# M7 register map
Registers are 32-bit, read-write, reset 0x0 unless marked. A register's access mark holds for its fields unless they carry their own. Offsets are from the block's base; lines under a group give offsets from that group; [hi:lo] are bit positions; {n}, {i} and the like mark numbered series; 'fields as' and 'values as' point back to an identical list; <NAME> marks a mode.

## Memory map
0xE000E010 STK size 0x11 — SysTick timer
0xE000E100 NVIC size 0x3C5 — Nested Vectored Interrupt Controller
0xE000ED00 SCB size 0x41 — System control block
0xE000ED90 MPU size 0x15 — Memory protection unit
0xE000EF34 FPU size 0xD — Floting point unit

## FPU — Floting point unit
Base 0xE000EF34
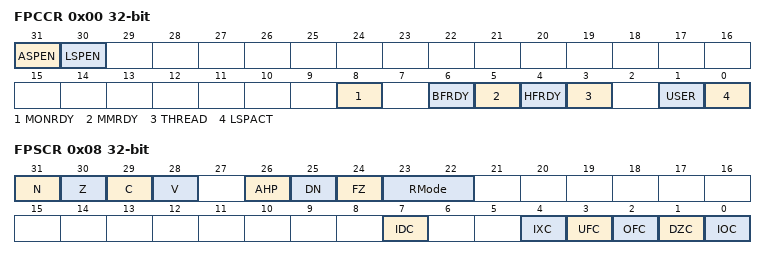
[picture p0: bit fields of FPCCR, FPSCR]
0x00 FPCCR — Floating-point context control register
  [31] ASPEN, [30] LSPEN, [8] MONRDY, [6] BFRDY, [5] MMRDY, [4] HFRDY, [3] THREAD, [1] USER, [0] LSPACT
0x04 FPCAR — Floating-point context address register
  [31:3] ADDRESS — Location of unpopulated floating-point
0x08 FPSCR — Floating-point status control register
  [31] N — Negative condition code flag
  [30] Z — Zero condition code flag
  [29] C — Carry condition code flag
  [28] V — Overflow condition code flag
  [26] AHP — Alternative half-precision control bit
  [25] DN — Default NaN mode control bit
  [24] FZ — Flush-to-zero mode control bit:
  [23:22] RMode — Rounding Mode control field
  [7] IDC — Input denormal cumulative exception bit.
  [4] IXC — Inexact cumulative exception bit
  [3] UFC — Underflow cumulative exception bit
  [2] OFC — Overflow cumulative exception bit
  [1] DZC — Division by zero cumulative exception bit.
  [0] IOC — Invalid operation cumulative exception bit

## MPU — Memory protection unit
Base 0xE000ED90
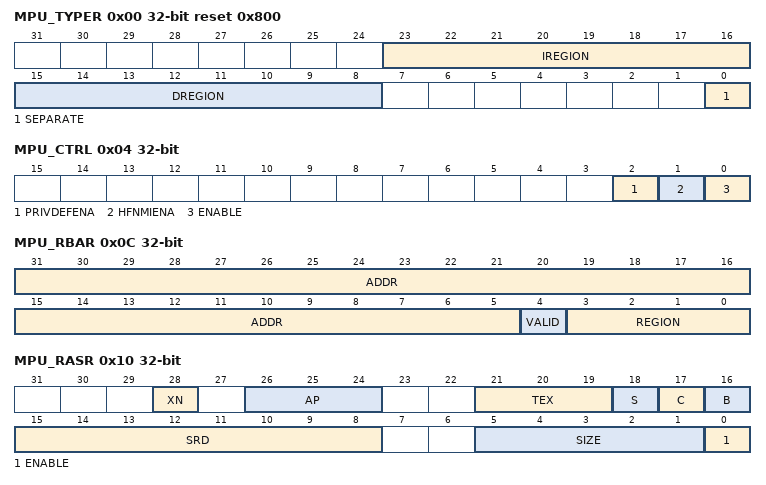
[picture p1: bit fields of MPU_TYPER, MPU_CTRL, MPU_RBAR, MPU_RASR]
0x00 MPU_TYPER ro reset 0x800 — MPU type register
  [23:16] IREGION — Number of MPU instruction regions
  [15:8] DREGION — Number of MPU data regions
  [0] SEPARATE — Separate flag
0x04 MPU_CTRL — MPU control register
  [2] PRIVDEFENA — Enable priviliged software access to default memory map
  [1] HFNMIENA — Enables the operation of MPU during hard fault
  [0] ENABLE — Enables the MPU
0x08 MPU_RNR — MPU region number register
  [7:0] REGION — MPU region
0x0C MPU_RBAR — MPU region base address register
  [31:5] ADDR — Region base address field
  [4] VALID — MPU region number valid
  [3:0] REGION — MPU region field
0x10 MPU_RASR — MPU region attribute and size register
  [28] XN — Instruction access disable bit
  [26:24] AP — Access permission
  [21:19] TEX — memory attribute
  [18] S — Shareable memory attribute
  [17] C — memory attribute
  [16] B — memory attribute
  [15:8] SRD — Subregion disable bits
  [5:1] SIZE — Size of the MPU protection region
  [0] ENABLE — Region enable bit.

## NVIC — Nested Vectored Interrupt Controller
Base 0xE000E100
{0x0+4i} ISER{i} (i=0..2) — Interrupt Set-Enable Register
  [31:0] SETENA
{0x80+4i} ICER{i} (i=0..2) — Interrupt Clear-Enable Register
  [31:0] CLRENA
{0x100+4i} ISPR{i} (i=0..2) — Interrupt Set-Pending Register
  [31:0] SETPEND
{0x180+4i} ICPR{i} (i=0..2) — Interrupt Clear-Pending Register
  [31:0] CLRPEND
{0x200+4i} IABR{i} ro (i=0..2) — Interrupt Active Bit Register
  [31:0] ACTIVE
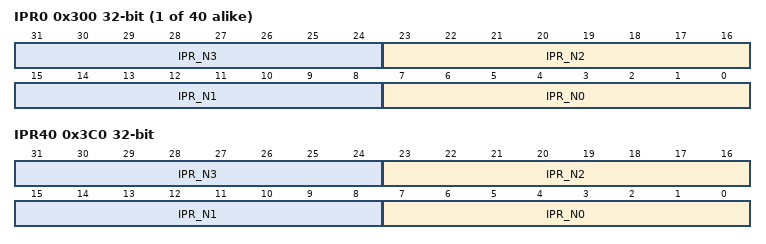
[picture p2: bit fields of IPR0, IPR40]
{0x300+4i} IPR{i} (i=0..39) — Interrupt Priority Register
  [8n+7:8n] IPR_N{n} (n=0..3)
0x3A0 ISER3 — Interrupt Set-Enable Register
  [31:0] SETENA
0x3A4 ISER4 — Interrupt Set-Enable Register
  [31:0] SETENA
0x3A8 ICER3 — Interrupt Clear-Enable Register
  [31:0] CLRENA
0x3AC ICER4 — Interrupt Clear-Enable Register
  [31:0] CLRENA
0x3B0 ISPR3 — Interrupt Set-Pending Register
  [31:0] SETPEND
0x3B4 ISPR4 — Interrupt Set-Pending Register
  [31:0] SETPEND
0x3B8 IABR3 ro — Interrupt Active Bit Register
  [31:0] ACTIVE
0x3BC IABR4 ro — Interrupt Active Bit Register
  [31:0] ACTIVE
0x3C0 IPR40 — Interrupt Priority Register
  [8n+7:8n] IPR_N{n} (n=0..3)

## SCB — System control block
Base 0xE000ED00
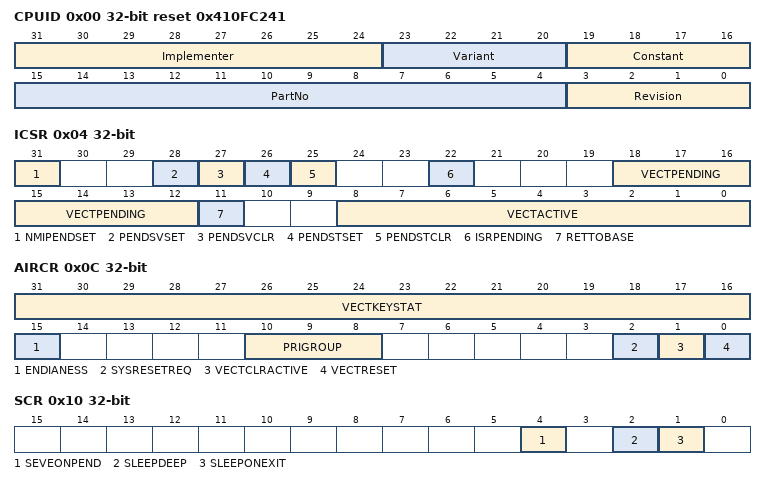
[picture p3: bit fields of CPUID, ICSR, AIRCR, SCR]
0x00 CPUID ro reset 0x410FC241 — CPUID base register
  [31:24] Implementer — Implementer code
  [23:20] Variant — Variant number
  [19:16] Constant — Reads as 0xF
  [15:4] PartNo — Part number of the processor
  [3:0] Revision — Revision number
0x04 ICSR — Interrupt control and state register
  [31] NMIPENDSET — NMI set-pending bit.
  [28] PENDSVSET — PendSV set-pending bit
  [27] PENDSVCLR — PendSV clear-pending bit
  [26] PENDSTSET — SysTick exception set-pending bit
  [25] PENDSTCLR — SysTick exception clear-pending bit
  [22] ISRPENDING — Interrupt pending flag
  [18:12] VECTPENDING — Pending vector
  [11] RETTOBASE — Return to base level
  [8:0] VECTACTIVE — Active vector
0x08 VTOR — Vector table offset register
  [29:9] TBLOFF — Vector table base offset field
0x0C AIRCR — Application interrupt and reset control register
  [31:16] VECTKEYSTAT — Register key
  [15] ENDIANESS
  [10:8] PRIGROUP
  [2] SYSRESETREQ
  [1] VECTCLRACTIVE
  [0] VECTRESET
0x10 SCR — System control register
  [4] SEVEONPEND — Send Event on Pending bit
  [2] SLEEPDEEP
  [1] SLEEPONEXIT
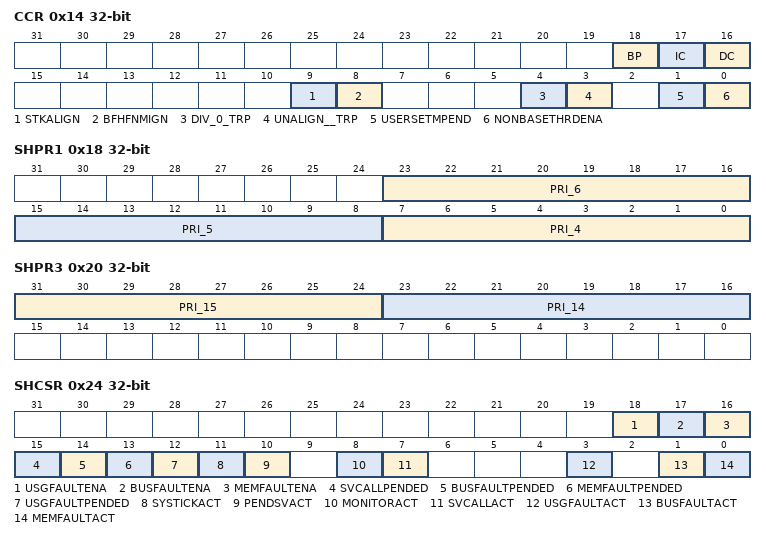
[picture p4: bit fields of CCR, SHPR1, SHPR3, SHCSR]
0x14 CCR — Configuration and control register
  [18] BP
  [17] IC
  [16] DC
  [9] STKALIGN
  [8] BFHFNMIGN
  [4] DIV_0_TRP
  [3] UNALIGN__TRP
  [1] USERSETMPEND
  [0] NONBASETHRDENA — Configures how the processor enters Thread mode
0x18 SHPR1 — System handler priority registers
  [23:16] PRI_6 — Priority of system handler 6
  [15:8] PRI_5 — Priority of system handler 5
  [7:0] PRI_4 — Priority of system handler 4
0x1C SHPR2 — System handler priority registers
  [31:24] PRI_11 — Priority of system handler 11
0x20 SHPR3 — System handler priority registers
  [31:24] PRI_15 — Priority of system handler 15
  [23:16] PRI_14 — Priority of system handler 14
0x24 SHCSR — System handler control and state register
  [18] USGFAULTENA — Usage fault enable bit
  [17] BUSFAULTENA — Bus fault enable bit
  [16] MEMFAULTENA — Memory management fault enable bit
  [15] SVCALLPENDED — SVC call pending bit
  [14] BUSFAULTPENDED — Bus fault exception pending bit
  [13] MEMFAULTPENDED — Memory management fault exception pending bit
  [12] USGFAULTPENDED — Usage fault exception pending bit
  [11] SYSTICKACT — SysTick exception active bit
  [10] PENDSVACT — PendSV exception active bit
  [8] MONITORACT — Debug monitor active bit
  [7] SVCALLACT — SVC call active bit
  [3] USGFAULTACT — Usage fault exception active bit
  [1] BUSFAULTACT — Bus fault exception active bit
  [0] MEMFAULTACT — Memory management fault exception active bit
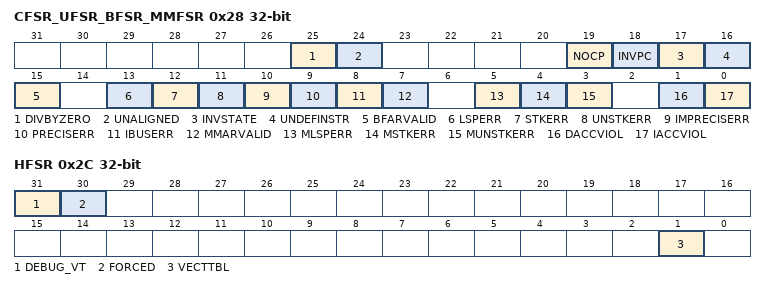
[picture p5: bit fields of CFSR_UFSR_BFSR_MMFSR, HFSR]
0x28 CFSR_UFSR_BFSR_MMFSR — Configurable fault status register
  [25] DIVBYZERO — Divide by zero usage fault
  [24] UNALIGNED — Unaligned access usage fault
  [19] NOCP — No coprocessor usage fault.
  [18] INVPC — Invalid PC load usage fault
  [17] INVSTATE — Invalid state usage fault
  [16] UNDEFINSTR — Undefined instruction usage fault
  [15] BFARVALID — Bus Fault Address Register (BFAR) valid flag
  [13] LSPERR — Bus fault on floating-point lazy state preservation
  [12] STKERR — Bus fault on stacking for exception entry
  [11] UNSTKERR — Bus fault on unstacking for a return from exception
  [10] IMPRECISERR — Imprecise data bus error
  [9] PRECISERR — Precise data bus error
  [8] IBUSERR — Instruction bus error
  [7] MMARVALID
  [5] MLSPERR
  [4] MSTKERR
  [3] MUNSTKERR
  [1] DACCVIOL
  [0] IACCVIOL
0x2C HFSR — Hard fault status register
  [31] DEBUG_VT — Reserved for Debug use
  [30] FORCED — Forced hard fault
  [1] VECTTBL — Vector table hard fault
0x34 MMFAR — Memory management fault address register
  [31:0] ADDRESS — Memory management fault address
0x38 BFAR — Bus fault address register
  [31:0] ADDRESS — Bus fault address

## STK — SysTick timer
Base 0xE000E010
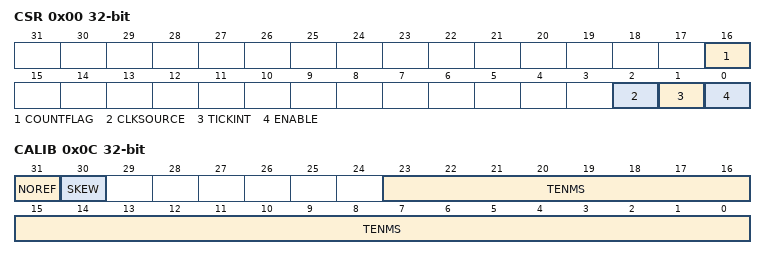
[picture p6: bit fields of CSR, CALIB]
0x00 CSR — SysTick control and status register
  [16] COUNTFLAG
  [2] CLKSOURCE — Clock source selection
  [1] TICKINT — SysTick exception request enable
  [0] ENABLE — Counter enable
0x04 RVR — SysTick reload value register
  [23:0] RELOAD — RELOAD value
0x08 CVR — SysTick current value register
  [23:0] CURRENT — Current counter value
0x0C CALIB — SysTick calibration value register
  [31] NOREF — NOREF flag. Reads as zero
  [30] SKEW — SKEW flag: Indicates whether the TENMS value is exact
  [23:0] TENMS — Calibration value
